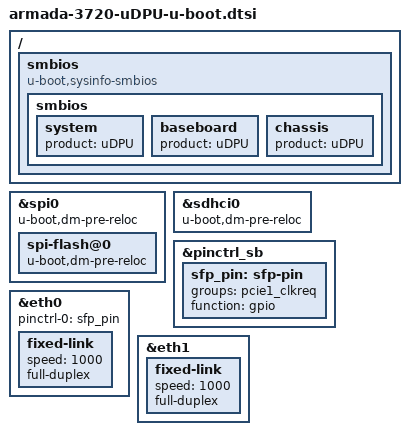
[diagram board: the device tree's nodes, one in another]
// SPDX-License-Identifier: GPL-2.0+

/ {
	smbios {
		compatible = "u-boot,sysinfo-smbios";

		smbios {
			system {
				product = "uDPU";
			};

			baseboard {
				product = "uDPU";
			};

			chassis {
				product = "uDPU";
			};
		};
	};
};

&spi0 {
	u-boot,dm-pre-reloc;

	spi-flash@0 {
		u-boot,dm-pre-reloc;
	};
};

&sdhci0 {
	u-boot,dm-pre-reloc;
};

&pinctrl_sb {
	sfp_pin: sfp-pin {
		groups = "pcie1_clkreq";
		function = "gpio";
	};
};

&eth0 {
	pinctrl-names = "default";
	pinctrl-0 = <&sfp_pin>;

	fixed-link {
		speed = <1000>;
		full-duplex;
	};
};

&eth1 {
	fixed-link {
		speed = <1000>;
		full-duplex;
	};
};
